# MB9BF10xR register map
File version: 1.7
Registers are 32-bit, read-write, reset 0x0 unless marked. A register's access mark holds for its fields unless they carry their own. Offsets are from the block's base; [hi:lo] are bit positions; {n}, {i} and the like mark numbered series; 'fields as' and 'values as' point back to an identical list.

## MFT_PPG — PPG Configuration
Base 0x40024000
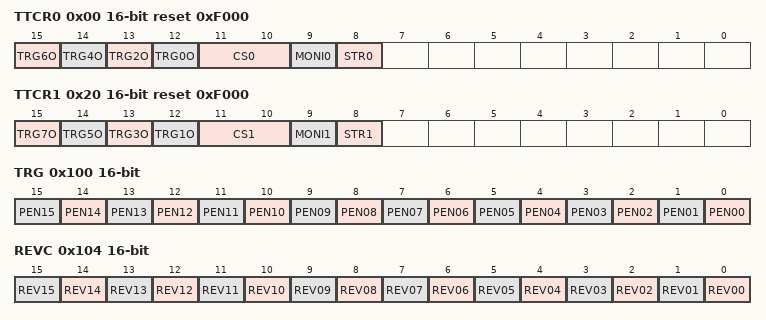
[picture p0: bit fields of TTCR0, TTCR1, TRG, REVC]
0x00 TTCR0 16-bit reset 0xF000 — PPG Start Trigger Control Register 0
  [15] TRG6O — PPG6 trigger stop bit
  [14] TRG4O — PPG4 trigger stop bit
  [13] TRG2O — PPG2 trigger stop bit
  [12] TRG0O — PPG0 trigger stop bit
  [11:10] CS0 — 8-bit UP counter clock select bits for comparison
  [9] MONI0 ro — 8-bit UP counter operation state monitor bit for comparison
  [8] STR0 — 8-bit UP counter operation enable bit for comparison
0x08 COMP0 16-bit (reset mask 0xFF00) — PPG Compare Register 0
0x0C COMP2 8-bit — PPG Compare Register 2
0x10 COMP4 16-bit (reset mask 0xFF00) — PPG Compare Register 4
0x14 COMP6 8-bit — PPG Compare Register 6
0x20 TTCR1 16-bit reset 0xF000 — PPG Start Trigger Control Register 1
  [15] TRG7O — PPG7 trigger stop bit
  [14] TRG5O — PPG5 trigger stop bit
  [13] TRG3O — PPG3 trigger stop bit
  [12] TRG1O — PPG1 trigger stop bit
  [11:10] CS1 — 8-bit UP counter clock select bits for comparison
  [9] MONI1 ro — 8-bit UP counter operation state monitor bit for comparison
  [8] STR1 — 8-bit UP counter operation enable bit for comparison
0x28 COMP1 16-bit (reset mask 0xFF00) — PPG Compare Register 1
0x2C COMP3 8-bit — PPG Compare Register 3
0x30 COMP5 16-bit (reset mask 0xFF00) — PPG Compare Register 5
0x34 COMP7 8-bit — PPG Compare Register 7
0x100 TRG 16-bit — PPG Start Register 0
  [n] PEN{n:02} (n=0..15) — PPG{n} Start Trigger bit
0x104 REVC 16-bit — Output Reverse Register 0
  [n] REV{n:02} (n=0..15) — PPG{n} Output Reverse Enable bit
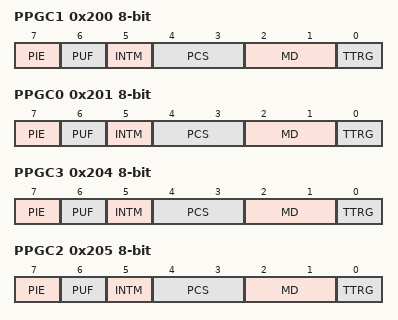
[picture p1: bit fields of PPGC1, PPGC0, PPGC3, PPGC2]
0x200 PPGC1 8-bit — PPG Operation Mode Control Register 1
  [7] PIE — PPG Interrupt Enable bit
  [6] PUF — PPG Counter Underflow bit
  [5] INTM — Interrupt Mode Select bit
  [4:3] PCS — PPG DOWN Counter Operation Clock Select bits
  [2:1] MD — PPG Operation Mode Set bits
  [0] TTRG — PPG start trigger select bit
0x201 PPGC0 8-bit — PPG Operation Mode Control Register 0
  fields as PPGC1
0x204 PPGC3 8-bit — PPG Operation Mode Control Register 3
  fields as PPGC1
0x205 PPGC2 8-bit — PPG Operation Mode Control Register 2
  fields as PPGC1
{0x208+4i} PRLL{i} 8-bit reset not defined (i=0..3) — PPG{i} Reload Registers Low
  [7:0] PRLL — Reload Registers Low
{0x209+4i} PRLH{i} 8-bit reset not defined (i=0..3) — PPG{i} Reload Registers High
  [7:0] PRLH — Reload Registers High
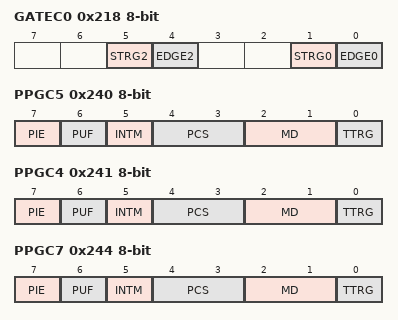
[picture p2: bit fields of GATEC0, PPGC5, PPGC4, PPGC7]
0x218 GATEC0 8-bit — PPG Gate Function Control Registers 0
  [5] STRG2 — Select a trigger for PPG2
  [4] EDGE2 — Select Start Effective Level for PPG2
  [1] STRG0 — Select a trigger for PPG0
  [0] EDGE0 — Select Start Effective Level for PPG0
0x240 PPGC5 8-bit — PPG Operation Mode Control Register 5
  fields as PPGC1
0x241 PPGC4 8-bit — PPG Operation Mode Control Register 4
  fields as PPGC1
0x244 PPGC7 8-bit — PPG Operation Mode Control Register 7
  fields as PPGC1
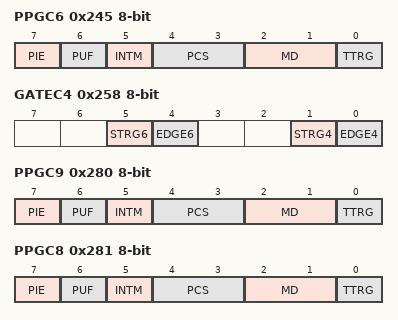
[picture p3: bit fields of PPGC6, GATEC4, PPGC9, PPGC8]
0x245 PPGC6 8-bit — PPG Operation Mode Control Register 6
  fields as PPGC1
{0x238+4i} PRLL{i} 8-bit reset not defined (i=4..7) — PPG{i} Reload Registers Low
  [7:0] PRLL — Reload Registers Low
{0x239+4i} PRLH{i} 8-bit reset not defined (i=4..7) — PPG{i} Reload Registers High
  [7:0] PRLH — Reload Registers High
0x258 GATEC4 8-bit — PPG Gate Function Control Registers 4
  [5] STRG6 — Select a trigger for PPG6
  [4] EDGE6 — Select Start Effective Level for PPG6
  [1] STRG4 — Select a trigger for PPG4
  [0] EDGE4 — Select Start Effective Level for PPG4
0x280 PPGC9 8-bit — PPG Operation Mode Control Register 9
  fields as PPGC1
0x281 PPGC8 8-bit — PPG Operation Mode Control Register 8
  fields as PPGC1
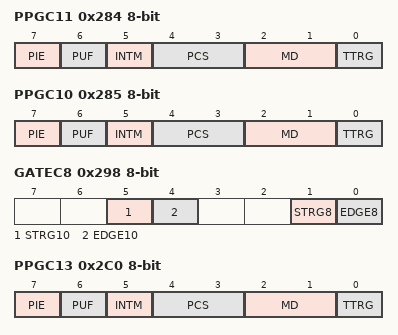
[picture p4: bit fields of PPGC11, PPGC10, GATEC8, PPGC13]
0x284 PPGC11 8-bit — PPG Operation Mode Control Register 11
  fields as PPGC1
0x285 PPGC10 8-bit — PPG Operation Mode Control Register 10
  fields as PPGC1
{0x268+4i} PRLL{i} 8-bit reset not defined (i=8..11) — PPG{i} Reload Registers Low
  [7:0] PRLL — Reload Registers Low
{0x269+4i} PRLH{i} 8-bit reset not defined (i=8..11) — PPG{i} Reload Registers High
  [7:0] PRLH — Reload Registers High
0x298 GATEC8 8-bit — PPG Gate Function Control Registers 8
  [5] STRG10 — Select a trigger for PPG10
  [4] EDGE10 — Select Start Effective Level for PPG10
  [1] STRG8 — Select a trigger for PPG8
  [0] EDGE8 — Select Start Effective Level for PPG8
0x2C0 PPGC13 8-bit — PPG Operation Mode Control Register 13
  fields as PPGC1
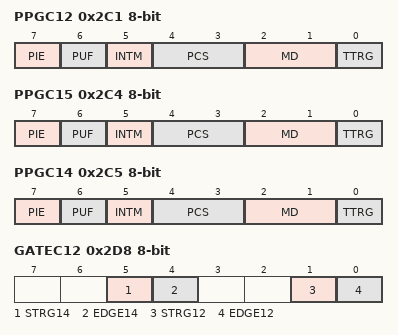
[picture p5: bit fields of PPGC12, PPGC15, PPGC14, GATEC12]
0x2C1 PPGC12 8-bit — PPG Operation Mode Control Register 12
  fields as PPGC1
0x2C4 PPGC15 8-bit — PPG Operation Mode Control Register 15
  fields as PPGC1
0x2C5 PPGC14 8-bit — PPG Operation Mode Control Register 14
  fields as PPGC1
{0x298+4i} PRLL{i} 8-bit reset not defined (i=12..15) — PPG{i} Reload Registers Low
  [7:0] PRLL — Reload Registers Low
{0x299+4i} PRLH{i} 8-bit reset not defined (i=12..15) — PPG{i} Reload Registers High
  [7:0] PRLH — Reload Registers High
0x2D8 GATEC12 8-bit — PPG Gate Function Control Registers 12
  [5] STRG14 — Select a trigger for PPG14
  [4] EDGE14 — Select Start Effective Level for PPG14
  [1] STRG12 — Select a trigger for PPG12
  [0] EDGE12 — Select Start Effective Level for PPG12

## Notices in the file
Licence Terms
FUJITSU SEMICONDUCTOR LIMITED (gLICENSORh) hereby grants and
you (gLICENSEEh) hereby accept a non transferable, non-exclusive
licence to use and copy the deliverables (gDeliverablesh) solely for
the purpose of; (i) developing LICENSEEfs development tools and
distributing such development tools to third parties; (ii) generating
derivative representations of the Deliverables to develop and debug
software for LICENSORfs targeted devices or device series identified
within the Deliverables, (together the gPurposeh) under the following
terms and conditions:
1. Ownership.
The Deliverables are the property of LICENSOR. LICENSEE acquires no
right, title or interest in the Deliverables other than the licence
rights granted herein.
2. Use.
LICENSEE shall only be permitted to use the Deliverables for the
Purpose. LICENSEE shall not reverse engineer, decompile or
disassemble the Deliverables, in whole or in part.
3. Copies.
All copies of the Deliverables must bear the same notice(s) contained
on the original copies of the Deliverables.
4. No Warranty.
THE DELIVERABLES ARE PROVIDED gAS ISh AND ANY EXPRESS, IMPLIED OR
STATUTORY WARRANTIES, INCLUDING, BUT NOT LIMITED TO, THE IMPLIED
WARRANTIES OF MERCHANTABILITY, SATISFACTORY QUALITY AND FITNESS FOR
A PARTICULAR PURPOSE ARE DISCLAIMED.
IN NO EVENT SHALL LICENSOR BE LIABLE FOR ANY DIRECT, INDIRECT,
INCIDENTAL, SPECIAL, EXEMPLARY, OR CONSEQUENTIAL DAMAGES HOWEVER CAUSED
AND ON ANY THEORY OF LIABILITY, WHETHER IN CONTRACT, STRICT LIABILITY,
OR TORT (INCLUDING NEGLIGENCE OR OTHERWISE) ARISING IN ANY WAY OUT OF
THE USE OF THE DELIVERABLES, EVEN IF ADVISED OF THE POSSIBILITY OF SUCH
DAMAGE.
LICENSEE EXPRESSLY ASSUMES ALL LIABILITIES AND RISKS, FOR USE OR
OPERATION OF THE DELIVERABLES.
5.In the event that LICENSEE receives early access to the Deliverables,
LICENSEE acknowledges and agrees that;
(a) notwithstanding the licence grants above, LICENSEE shall only be
permitted to use the Deliverables solely internally for evaluation and
providing feedback to LICENSOR;
(b) except with respect to the limited licence grants in 5(a), LICENSEE
shall be subject to all of the terms and conditions set out above; and
(c) the Deliverables are confidential information and LICENSEE shall
maintain in confidence the Deliverables and apply security measures no
less stringent than the measures that LICENSEE applies to its own like
information, but not less than a reasonable degree of care, to prevent
unauthorised disclosure and use of the Deliverables.
